AUTOSAR XML (schema 4-0-3)
package /Actuators
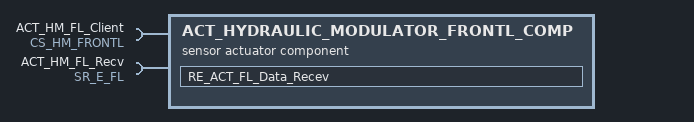
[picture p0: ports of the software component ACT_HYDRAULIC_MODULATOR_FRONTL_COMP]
  sensor actuator sw component type ACT_HYDRAULIC_MODULATOR_FRONTL_COMP
    require port ACT_HM_FL_Client: required-interface=CS_HM_FRONTL
    require port ACT_HM_FL_Recv: required-interface=SR_E_FL
    behavior IB_HM_FL
      data received event DataReceivedEvent_0: start-on-event=RE_ACT_FL_Data_Recev, data=ACT_HM_FL_Recv.modedata
      runnable RE_ACT_FL_Data_Recev: symbol=RE_ACT_FL_Data_Recev_func
        data-receive-point-by-values:
          access DRPV_modedata_0: accessed-variable=ACT_HM_FL_Recv.modedata
        sync call SynchronousServerCallPoint_0: operation=ACT_HM_FL_Client.set_E_op
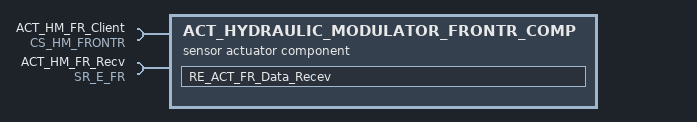
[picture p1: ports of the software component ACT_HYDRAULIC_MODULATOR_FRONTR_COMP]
  sensor actuator sw component type ACT_HYDRAULIC_MODULATOR_FRONTR_COMP
    require port ACT_HM_FR_Client: required-interface=CS_HM_FRONTR
    require port ACT_HM_FR_Recv: required-interface=SR_E_FR
    behavior IB_HM_FR
      data received event DataReceivedEvent_0: start-on-event=RE_ACT_FR_Data_Recev, data=ACT_HM_FR_Recv.modedata
      runnable RE_ACT_FR_Data_Recev: symbol=RE_ACT_FR_Data_Recev_func
        data-receive-point-by-values:
          access DRPV_modedata_0: accessed-variable=ACT_HM_FR_Recv.modedata
        sync call SynchronousServerCallPoint_0: operation=ACT_HM_FR_Client.set_E_op
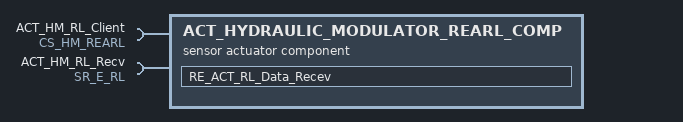
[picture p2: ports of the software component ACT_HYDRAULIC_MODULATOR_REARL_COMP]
  sensor actuator sw component type ACT_HYDRAULIC_MODULATOR_REARL_COMP
    require port ACT_HM_RL_Client: required-interface=CS_HM_REARL
    require port ACT_HM_RL_Recv: required-interface=SR_E_RL
    behavior IB_HM_RL
      data received event DataReceivedEvent_0: start-on-event=RE_ACT_RL_Data_Recev, data=ACT_HM_RL_Recv.modedata
      runnable RE_ACT_RL_Data_Recev: symbol=RE_ACT_RL_Data_Recev_func
        data-receive-point-by-values:
          access DRPV_modedata_0: accessed-variable=ACT_HM_RL_Recv.modedata
        sync call SynchronousServerCallPoint_0: operation=ACT_HM_RL_Client.set_E_op
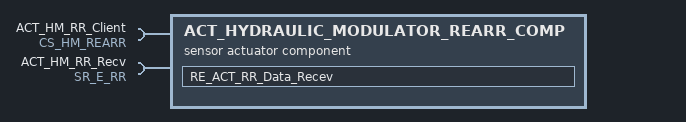
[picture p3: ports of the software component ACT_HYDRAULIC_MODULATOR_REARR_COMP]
  sensor actuator sw component type ACT_HYDRAULIC_MODULATOR_REARR_COMP
    require port ACT_HM_RR_Client: required-interface=CS_HM_REARR
    require port ACT_HM_RR_Recv: required-interface=SR_E_RR
    behavior IB_HM_RR
      data received event DataReceivedEvent_0: start-on-event=RE_ACT_RR_Data_Recev, data=ACT_HM_RR_Recv.modedata
      runnable RE_ACT_RR_Data_Recev: symbol=RE_ACT_RR_Data_Recev_func
        data-receive-point-by-values:
          access DRPV_modedata_0: accessed-variable=ACT_HM_RR_Recv.modedata
        sync call SynchronousServerCallPoint_0: operation=ACT_HM_RR_Client.set_E_op
  4 x client server interface:
    CS_HM_FRONTL
      operation set_E_op
        arg volt: type=sint16, direction=IN, server-argument-impl-policy=USE-ARGUMENT-TYPE
    CS_HM_FRONTR
      operation set_E_op
        arg volt: type=sint16, direction=IN, server-argument-impl-policy=USE-ARGUMENT-TYPE
    CS_HM_REARL
      operation set_E_op
        arg volt: type=sint16, direction=IN, server-argument-impl-policy=USE-ARGUMENT-TYPE
    CS_HM_REARR
      operation set_E_op
        arg volt: type=sint16, direction=IN, server-argument-impl-policy=USE-ARGUMENT-TYPE
  4 x sender receiver interface:
    SR_E_FL
      data modedata: type=sint8
    SR_E_FR
      data modedata: type=sint8
    SR_E_RL
      data modedata: type=sint8
    SR_E_RR
      data modedata: type=sint8
